# TLE984x register map
Vendor: Infineon Technologies AG; File version: 1.6
CPU: CM0 r0p0, little endian, no MPU, no FPU, 2 interrupt priority bits
Registers are 32-bit, read-write, no defined reset value unless marked. A register's access mark holds for its fields unless they carry their own. Offsets are from the block's base; [hi:lo] are bit positions; 'fields as' and 'values as' point back to an identical list.

## TIMER2
Base 0x48004000
Same registers: TIMER21 0x48005000
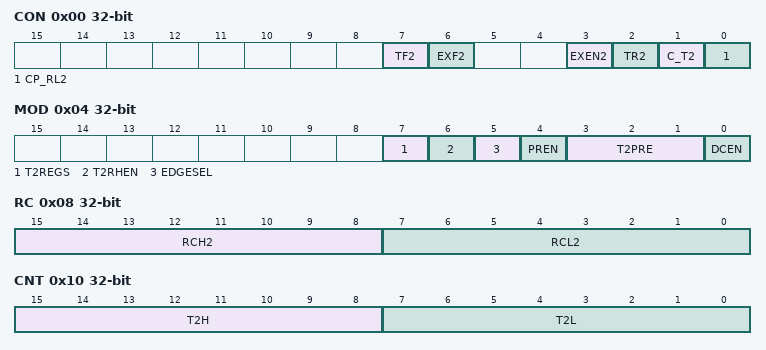
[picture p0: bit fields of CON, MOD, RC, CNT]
0x00 CON access per field — Timer 2 Control Register
  [7] TF2 ro — Timer 2 Overflow/Underflow Flag
  [6] EXF2 ro — Timer 2 External Flag
  [3] EXEN2 rw — Timer 2 External Enable Control
    0=DISABLED (External events are disabled.); 1=ENABLED (External events are enabled in Capture/Reload Mode.)
  [2] TR2 rw — Timer 2 Start/Stop Control
    0=STOP (Timer 2.); 1=START (Timer 2.)
  [1] C_T2 rw — Timer or Counter Select
    0=Timer (function selected.); 1=Count (upon negative edge at pin T2.)
  [0] CP_RL2 rw — Capture/Reload Select
    0=Reload (upon overflow or upon negative/positive transition at pin T2EX (when EXEN2 = 1).); 1=Capture (Timer 2 data register contents on the negative/positive transition at pin T2EX, provided EXEN2 = 1.The negative or positive transition at Pin T2EX is selected by bit EDGESEL.)
0x04 MOD — Timer 2 Mode Register
  [7] T2REGS — Edge Select for Timer 2 External Start
    0=FALLING (The falling edge at Pin T2EX is selected.); 1=RISING (The rising edge at Pin T2EX is selected.)
  [6] T2RHEN — Timer 2 External Start Enable
    0=DISABLED (Timer 2 External Start is disabled.); 1=ENABLED (Timer 2 External Start is enabled.)
  [5] EDGESEL — Edge Select in Capture Mode/Reload Mode
    values as T2REGS
  [4] PREN — Prescaler Enable
    0=DISABLED (Prescaler is disabled and the 2 or 12 divider takes effect.); 1=ENABLED (Prescaler is enabled (see T2PRE bit) and the 2 or 12 divider is bypassed.)
  [3:1] T2PRE — Timer 2 Prescaler Bit
    0=DIV1 (fT2 = fsys); 1=DIV2 (fT2 = fsys / 2); 2=DIV4 (DfT2 = fsys / 4); 3=DIV8 (fT2 = fsys / 8); 4=DIV16 (fT2 = fsys / 16); 5=DIV32 (fT2 = fsys / 32); 6=DIV64 (fT2 = fsys / 64); 7=DIV128 (fT2 = fsys / 128)
  [0] DCEN — Up/Down Counter Enable
    0=DISABLED (Up/Down Counter function is disabled); 1=ENABLED (Up/Down Counter function is enabled and controlled by pin T2EX (Up = 1, Down = 0))
0x08 RC — Timer 2 Reload/Capture Register
  [15:8] RCH2 — Reload/Capture Value
  [7:0] RCL2 — Reload/Capture Value
0x10 CNT — Timer 2 Count Register
  [15:8] T2H — Timer 2 Value
  [7:0] T2L — Timer 2 Value
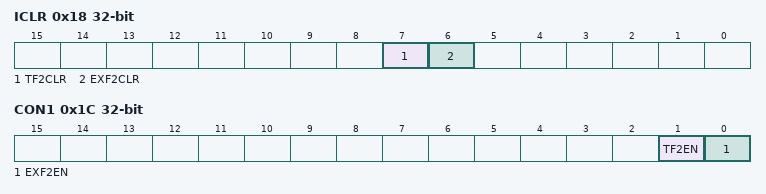
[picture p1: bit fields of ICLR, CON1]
0x18 ICLR wo — Timer 2 Interrupt Clear Register
  [7] TF2CLR — Overflow/Underflow Interrupt Clear Flag
    0=N/A (Overflow/underflow interrupt is not cleared.); 1=Clear (Overflow/underflow interrupt)
  [6] EXF2CLR — External Interrupt Clear Flag
    0=N/A (External interrupt is not cleared.); 1=Clear (External interrupt)
0x1C CON1 — Timer 2 Control Register 1
  [1] TF2EN — Overflow/Underflow Interrupt Enable
    0=DISABLE (Overflow/underflow interrupt.); 1=ENABLE (Overflow/underflow interrupt.)
  [0] EXF2EN — External Interrupt Enable
    0=DISABLE (External interrupt.); 1=ENABLE (External interrupt)

## UART1
Base 0x48020000
Same registers: UART2 0x48022000
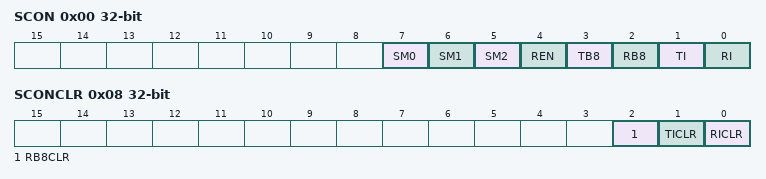
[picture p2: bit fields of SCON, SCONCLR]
0x00 SCON — Serial Channel Control Register
  [7] SM0 — Serial Port Operating Mode Selection
  [6] SM1 — Serial Port Operating Mode Selection
  [5] SM2 — Enable Serial Port Multiprocessor Communication in Modes 2 and 3
  [4] REN — Enable Receiver of Serial Port
    0=Serial reception is disabled; 1=Serial reception is enabled
  [3] TB8 — Serial Port Transmitter Bit 9
  [2] RB8 — Serial Port Receiver Bit 9
  [1] TI — Transmit Interrupt Flag
  [0] RI — Receive Interrupt Flag
0x04 SBUF — Serial Data Buffer
  [7:0] VAL — Serial Interface Buffer Register
0x08 SCONCLR wo — Serial Channel Control Clear Register
  [2] RB8CLR — SCON.RB8 Clear Flag
    0=RB8 Flag is not cleared; 1=RB8 Flag is cleared
  [1] TICLR — SCON.TI Clear Flag
    0=TI Flag is not cleared; 1=TI Flag is cleared
  [0] RICLR — SCON.RI Clear Flag
    0=RI Flag is not cleared; 1=RI Flag is cleared
